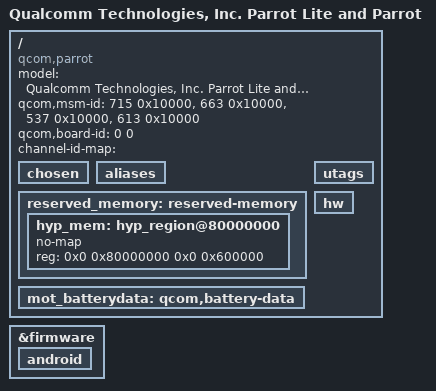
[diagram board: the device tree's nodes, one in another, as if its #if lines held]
/dts-v1/;

#if __has_include(<generated/autoconf.h>)
#include <generated/autoconf.h>
#endif

#include "parrot.dtsi"

/ {
	model = "Qualcomm Technologies, Inc. Parrot Lite and Parrot";
	compatible = "qcom,parrot";
	qcom,msm-id = <715 0x10000>, <663 0x10000>, <537 0x10000>, <613 0x10000>;
	qcom,board-id = <0 0>;
	channel-id-map = "";
/*
 * Some nodes need labels assigned to appear in __symbols__
 */
	chosen: chosen { };
	aliases: aliases { };
	reserved_memory: reserved-memory { };
	mot_batterydata: qcom,battery-data { };
	utags: utags { };
	hw: hw { };
};

&reserved_memory {
	/delete-node/ qcom_ramoops;
	/delete-node/ hyp_region1@0x82200000;

#if defined(CONFIG_PAROS_DTB)
	/delete-node/ hyp_region@0x83600000;

	hyp_mem: hyp_region@80000000 {
		no-map;
		reg = <0x0 0x80000000 0x0 0x600000>;
	};
#endif
};

&firmware {
	android {
		/delete-node/ fstab;
	};
};

/delete-node/ &mem_offline;
